# RL7005_IP_SVD register map
Vendor: Realtek
Registers are 32-bit, read-write, reset 0x0 unless marked. A register's access mark holds for its fields unless they carry their own. Offsets are from the block's base; [hi:lo] are bit positions; <NAME> marks a mode.

## PSRAM_PHY_REG
Base 0x4011F000
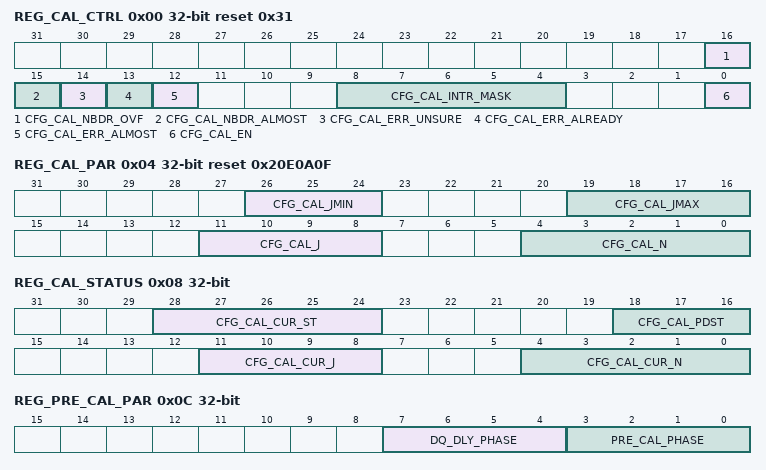
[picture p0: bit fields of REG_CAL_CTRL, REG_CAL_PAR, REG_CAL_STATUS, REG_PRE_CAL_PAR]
0x00 REG_CAL_CTRL access per field reset 0x31
  [16] CFG_CAL_NBDR_OVF ro — The N reachs the boundary , which is 0 or Nmax . Cleared by write 1 .
  [15] CFG_CAL_NBDR_ALMOST ro — The N-J or N+J reachs the boundary , which is 0 or Nmax . Cleared by write 1 .
  [14] CFG_CAL_ERR_UNSURE ro — The Pre N/J may cause current burst receive error , but it is not sure because the burst len is too small. Cleared by write 1 .
  [13] CFG_CAL_ERR_ALREADY ro — The Pre N/J may cause current burst receive error , even change J to Jmin , the error still remain . Cleared by write 1 .
  [12] CFG_CAL_ERR_ALMOST ro — The current burst receive correct , but next burst will set J = Jmin . Cleared by write 1 .
  [8:4] CFG_CAL_INTR_MASK rw — Calibration fail interrupt mask , every bit control one event above (1: enable , 0: disable) [0] : err almost [1] : err already [2] : err unsure [3] : nbdr almost [4] : nbdr ovf
  [0] CFG_CAL_EN rw — Hardware auto calibration enable , if disable , N,J will be fixed .
0x04 REG_CAL_PAR reset 0x20E0A0F
  [26:24] CFG_CAL_JMIN — Minimum J . Hardware may adjust J , if J reach this value , an interrup will be raised to alerm software.
  [19:16] CFG_CAL_JMAX — Maximum J . Hardware may adjust J , but will not exceed this value.
  [11:8] CFG_CAL_J — Initial value J calibrated by software .
  [4:0] CFG_CAL_N — Initial value N calibrated by software .
0x08 REG_CAL_STATUS ro
  [28:24] CFG_CAL_CUR_ST — Calibration current state . Cleared by write all 1 .
  [18:16] CFG_CAL_PDST — Calibration check result for last read burst . [0] : indicate phase n+j , if 1 , means dn == dn+j [1] : indicate phase n-j , if 1 , means dn == dn-j [2] : if 1 , means the state is under j = jmin condition
  [11:8] CFG_CAL_CUR_J — Current value J read from hardware.
  [4:0] CFG_CAL_CUR_N — Current value N read from hardware.
0x0C REG_PRE_CAL_PAR
  [7:4] DQ_DLY_PHASE — 8-tap delay line to adjust dq[7:0] phase, delay dq[7:0], rwds no change min: 0, max: 8 pad_rwds -------------------------> calibration pad_dq[7:0] -> delay x-tap -> calibration
  [3:0] PRE_CAL_PHASE — 8-tap delay line to adjust rwds phase, delay rwds, dq[7:0] no change min: 0, max: 8 pad_rwds -> delay x-tap -> calibration pad_dq[7:0] -------------------> calibration
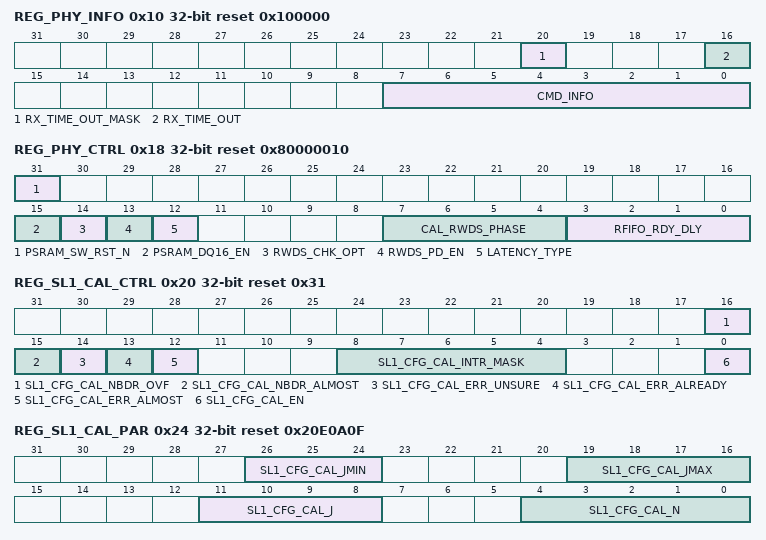
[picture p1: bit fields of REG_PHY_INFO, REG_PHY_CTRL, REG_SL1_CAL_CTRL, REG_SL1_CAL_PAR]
0x10 REG_PHY_INFO access per field reset 0x100000
  [20] RX_TIME_OUT_MASK rw — read time out interrupt mask
  [16] RX_TIME_OUT ro — read time out interrupt if there's no DQS/DQ from psram, write 1 to clear
  [7:0] CMD_INFO ro — Command information, 1st Byte of Command/Address transaction
0x18 REG_PHY_CTRL reset 0x80000010
  [31] PSRAM_SW_RST_N — low active, except for phy register(using system reset), psram software reset: psram, phy_ctrl, calibration
  [15] PSRAM_DQ16_EN — 1: enable to support DQ16 psram
  [14] RWDS_CHK_OPT — 0: synced psram_rwds_i direct to controller 1: only check psram_rwds_i at last valid cycle of CA stage, sync this pulse to controller
  [13] RWDS_PD_EN — psram_phy can control PD pin of rwds iopad, bypass high-Z state at CMD/ADDR stage
  [12] LATENCY_TYPE — set this bit according to spic & psram latency settings 0: variable latency 1: fixed latency
  [7:4] CAL_RWDS_PHASE — one-hot phase select, delay cal_rwds to push sampling data into rfifo
  [3:0] RFIFO_RDY_DLY — variable latency: delay read data cycles(phy clk) after detecting first DQS rising edge, must < 4 fixed latency: delay read data cycles(phy clk) after asserting spi_rx_data_en, must > 5 4*read_latency - rd_dummy_length + rfifo_rdy_dly = in_physical_cyc
0x20 REG_SL1_CAL_CTRL access per field reset 0x31
  [16] SL1_CFG_CAL_NBDR_OVF ro — The N reachs the boundary , which is 0 or Nmax . Cleared by write 1 .
  [15] SL1_CFG_CAL_NBDR_ALMOST ro — The N-J or N+J reachs the boundary , which is 0 or Nmax . Cleared by write 1 .
  [14] SL1_CFG_CAL_ERR_UNSURE ro — The Pre N/J may cause current burst receive error , but it is not sure because the burst len is too small. Cleared by write 1 .
  [13] SL1_CFG_CAL_ERR_ALREADY ro — The Pre N/J may cause current burst receive error , even change J to Jmin , the error still remain . Cleared by write 1 .
  [12] SL1_CFG_CAL_ERR_ALMOST ro — The current burst receive correct , but next burst will set J = Jmin . Cleared by write 1 .
  [8:4] SL1_CFG_CAL_INTR_MASK rw — Calibration fail interrupt mask , every bit control one event above (1: enable , 0: disable) [0] : err almost [1] : err already [2] : err unsure [3] : nbdr almost [4] : nbdr ovf
  [0] SL1_CFG_CAL_EN rw — Hardware auto calibration enable , if disable , N,J will be fixed .
0x24 REG_SL1_CAL_PAR reset 0x20E0A0F
  [26:24] SL1_CFG_CAL_JMIN — Minimum J . Hardware may adjust J , if J reach this value , an interrup will be raised to alerm software.
  [19:16] SL1_CFG_CAL_JMAX — Maximum J . Hardware may adjust J , but will not exceed this value.
  [11:8] SL1_CFG_CAL_J — Initial value J calibrated by software .
  [4:0] SL1_CFG_CAL_N — Initial value N calibrated by software .
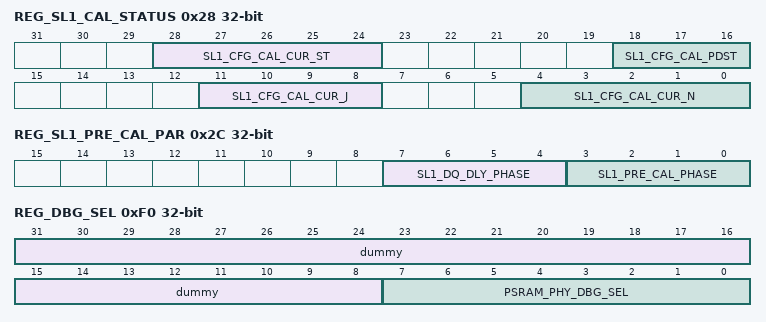
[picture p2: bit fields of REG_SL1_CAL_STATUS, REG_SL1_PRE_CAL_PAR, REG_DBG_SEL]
0x28 REG_SL1_CAL_STATUS ro
  [28:24] SL1_CFG_CAL_CUR_ST — Calibration current state . Cleared by write all 1 .
  [18:16] SL1_CFG_CAL_PDST — Calibration check result for last read burst . [0] : indicate phase n+j , if 1 , means dn == dn+j [1] : indicate phase n-j , if 1 , means dn == dn-j [2] : if 1 , means the state is under j = jmin condition
  [11:8] SL1_CFG_CAL_CUR_J — Current value J read from hardware.
  [4:0] SL1_CFG_CAL_CUR_N — Current value N read from hardware.
0x2C REG_SL1_PRE_CAL_PAR
  [7:4] SL1_DQ_DLY_PHASE — 8-tap delay line to adjust dq[7:0] phase, delay dq[7:0], rwds no change min: 0, max: 8 pad_rwds -------------------------> calibration pad_dq[7:0] -> delay x-tap -> calibration
  [3:0] SL1_PRE_CAL_PHASE — 8-tap delay line to adjust rwds phase, delay rwds, dq[7:0] no change min: 0, max: 8 pad_rwds -> delay x-tap -> calibration pad_dq[7:0] -------------------> calibration
0xF0 REG_DBG_SEL
  [31:8] dummy
  [7:0] PSRAM_PHY_DBG_SEL — psram phy debug select signal.
0xF8 REG_DBG_INFO ro
  [31:0] PSRAM_PHY_DBG — psram phy debug signals.
